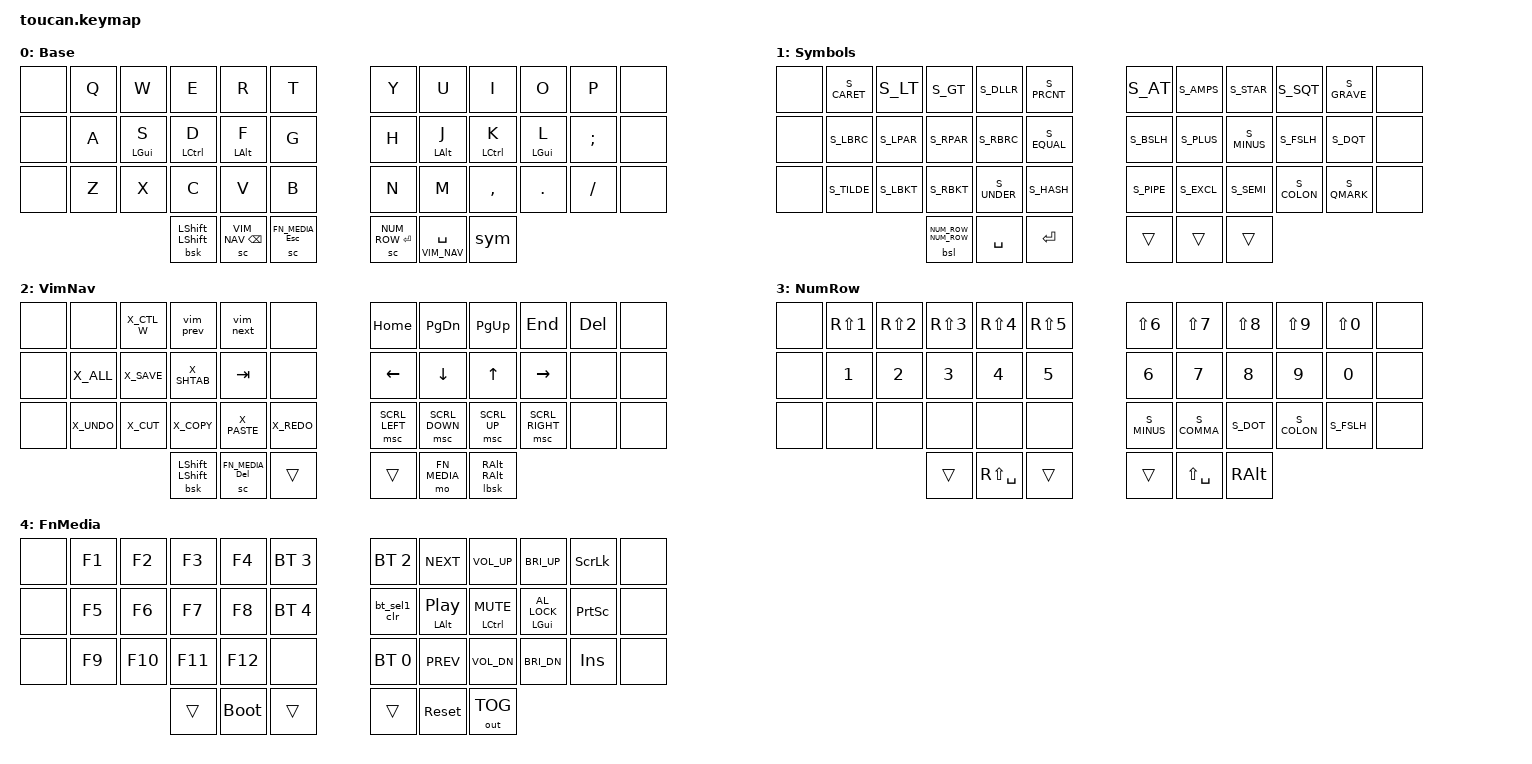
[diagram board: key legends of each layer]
/* SPDX-License-Identifier: MIT
 * Toucan v1 only: Selenium HRM, Vim variant, native Ergo-L on the host.
 * Adapted from OneDeadKey/zmk-config-aekeynox @ 3cadeede766f31bc1e34d7c9d8ee918073cf8478.
 * See THIRD_PARTY_NOTICES.md. HID names below are not the Ergo-L legends.
 */
#include <behaviors.dtsi>
#include <dt-bindings/zmk/keys.h>
#include <dt-bindings/zmk/bt.h>
#include <dt-bindings/zmk/outputs.h>

/* Selenium's keyboard-wheel speed; the physical touchpad keeps its own scaler. */
#define ZMK_POINTING_DEFAULT_SCRL_VAL 25
#include <dt-bindings/zmk/pointing.h>

#include "layers.h"
#include "ergol.h"
#include "selenium-behaviors.dtsi"

/* Each row has 12 bindings. Outer columns are deliberately &none on ALL layers.
 * Matrix indices: 0..11, 12..23, 24..35, then thumbs 36..41, left to right.
 * The shield fallback includes this file too: there is only one active keymap.
 */
/ {
    keymap {
        compatible = "zmk,keymap";

        base {
            display-name = "Base";
            bindings = <
                &none  &kp Q &kp W         &kp E          &kp R          &kp T  &kp Y &kp U         &kp I          &kp O         &kp P     &none
                &none  &kp A &hrm LGUI S   &hrm LCTRL D   &hrm LALT F   &kp G  &kp H &hrm LALT J   &hrm LCTRL K   &hrm LGUI L   &kp SEMI  &none
                &none  &kp Z &kp X         &kp C          &kp V          &kp B  &kp N &kp M         &kp COMMA      &kp DOT       &kp FSLH  &none
                    &bsk LSHIFT LSHIFT  &sc VIM_NAV BACKSPACE  &sc FN_MEDIA ESCAPE   &sc NUM_ROW ENTER  &ltp VIM_NAV SPACE  &sym
            >;
        };

        symbols {
            display-name = "Symbols";
            bindings = <
                &none  S_CARET S_LT   S_GT   S_DLLR  S_PRCNT  S_AT   S_AMPS S_STAR  S_SQT   S_GRAVE  &none
                &none  S_LBRC  S_LPAR S_RPAR S_RBRC  S_EQUAL  S_BSLH S_PLUS S_MINUS S_FSLH  S_DQT    &none
                &none  S_TILDE S_LBKT S_RBKT S_UNDER S_HASH   S_PIPE S_EXCL S_SEMI  S_COLON S_QMARK  &none
                    &bsl NUM_ROW NUM_ROW  &kp SPACE  &kp ENTER   &trans  &trans  &trans
            >;
        };

        vim_nav {
            display-name = "VimNav";
            bindings = <
                &none  &none  X_CTL_W &vim_prev &vim_next &none   &kp HOME        &kp PG_DN       &kp PG_UP     &kp END         &kp DEL  &none
                &none  X_ALL  X_SAVE  X_SHTAB   &kp TAB   &none   &kp LEFT        &kp DOWN        &kp UP        &kp RIGHT       &none    &none
                &none  X_UNDO X_CUT   X_COPY    X_PASTE   X_REDO  &msc SCRL_LEFT  &msc SCRL_DOWN  &msc SCRL_UP  &msc SCRL_RIGHT &none    &none
                    &bsk LSHIFT LSHIFT  &sc FN_MEDIA DEL  &trans   &trans  &mo FN_MEDIA  &lbsk RALT RALT
            >;
        };

        num_row {
            display-name = "NumRow";
            bindings = <
                &none  &kp RS(N1) &kp RS(N2) &kp RS(N3) &kp RS(N4) &kp RS(N5)  &kp LS(N6) &kp LS(N7) &kp LS(N8) &kp LS(N9) &kp LS(N0)  &none
                &none  &kp N1     &kp N2     &kp N3     &kp N4     &kp N5      &kp N6     &kp N7     &kp N8     &kp N9     &kp N0      &none
                &none  &none      &none      &none      &none      &none       S_MINUS    S_COMMA    S_DOT      S_COLON    S_FSLH      &none
                    &trans  &kp RS(SPACE)  &trans   &trans  &kp LS(SPACE)  &kp RALT
            >;
        };

        fn_media {
            display-name = "FnMedia";
            bindings = <
                &none  &kp F1 &kp F2  &kp F3  &kp F4  &bt BT_SEL 3  &bt BT_SEL 2  &kp C_NEXT       &kp C_VOL_UP       &kp C_BRI_UP          &kp SLCK   &none
                &none  &kp F5 &kp F6  &kp F7  &kp F8  &bt BT_SEL 4  &bt_sel1_clr  &hrm LALT C_PP   &hrm LCTRL C_MUTE  &hrm LGUI C_AL_LOCK   &kp PSCRN  &none
                &none  &kp F9 &kp F10 &kp F11 &kp F12 &none         &bt BT_SEL 0  &kp C_PREV       &kp C_VOL_DN       &kp C_BRI_DN          &kp INS    &none
                    &trans  &bootloader  &trans   &trans  &sys_reset  &out OUT_TOG
            >;
        };
    };
};
